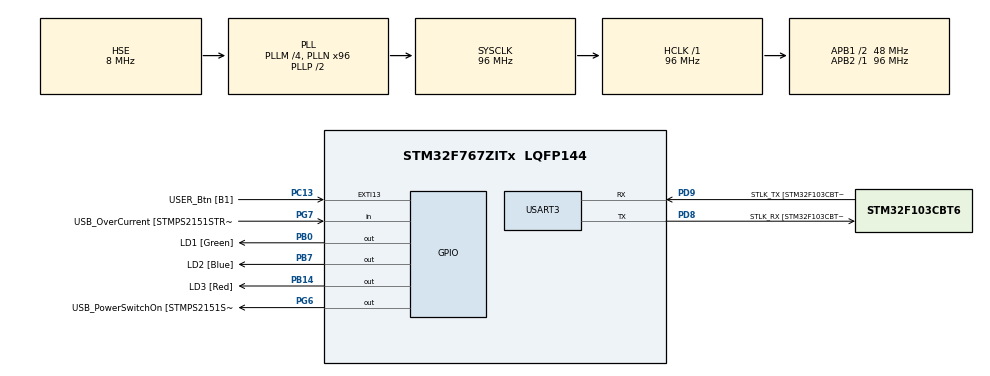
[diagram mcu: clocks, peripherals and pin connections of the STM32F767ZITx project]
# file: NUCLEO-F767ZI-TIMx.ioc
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Mcu.Family=STM32F7
Mcu.Name=STM32F767ZITx
Mcu.Package=LQFP144
NVIC.PriorityGroup=NVIC_PRIORITYGROUP_4
PA13.GPIO_Label=TMS
PA13.Mode=Serial_Wire
PA13.Signal=SYS_JTMS-SWDIO
PA14.GPIO_Label=TCK
PA14.Mode=Serial_Wire
PA14.Signal=SYS_JTCK-SWCLK
PB0.GPIO_Label=LD1 [Green]
PB0.Signal=GPIO_Output
PB14.GPIO_Label=LD3 [Red]
PB14.Signal=GPIO_Output
PB3.GPIO_Label=SWO
PB3.Signal=SYS_JTDO-SWO
PB7.GPIO_Label=LD2 [Blue]
PB7.Signal=GPIO_Output
PC13.GPIO_Label=USER_Btn [B1]
PC13.Signal=GPXTI13
PC14/OSC32_IN.Mode=LSE-External-Oscillator
PC14/OSC32_IN.Signal=RCC_OSC32_IN
PC15/OSC32_OUT.Mode=LSE-External-Oscillator
PC15/OSC32_OUT.Signal=RCC_OSC32_OUT
PD8.GPIO_Label=STLK_RX [STM32F103CBT6_PA3]
PD8.Mode=Asynchronous
PD8.Signal=USART3_TX
PD9.GPIO_Label=STLK_TX [STM32F103CBT6_PA2]
PD9.Mode=Asynchronous
PD9.Signal=USART3_RX
PG6.GPIO_Label=USB_PowerSwitchOn [STMPS2151STR_EN]
PG6.Signal=GPIO_Output
PG7.GPIO_Label=USB_OverCurrent [STMPS2151STR_FAULT]
PG7.Signal=GPIO_Input
PH0/OSC_IN.GPIO_Label=MCO [STM32F103CBT6_PA8]
PH0/OSC_IN.Mode=HSE-External-Clock-Source
PH0/OSC_IN.Signal=RCC_OSC_IN
PH1/OSC_OUT.Mode=HSE-External-Clock-Source
PH1/OSC_OUT.Signal=RCC_OSC_OUT
ProjectManager.HeapSize=0x200
ProjectManager.StackSize=0x400
ProjectManager.TargetToolchain=STM32CubeIDE
RCC.48MHZClocksFreq_Value=24000000
RCC.AHBFreq_Value=96000000
RCC.APB1CLKDivider=RCC_HCLK_DIV2
RCC.APB1Freq_Value=48000000
RCC.APB1TimFreq_Value=96000000
RCC.APB2Freq_Value=96000000
RCC.APB2TimFreq_Value=96000000
RCC.CortexFreq_Value=96000000
RCC.HCLKFreq_Value=96000000
RCC.HSE_VALUE=8000000
RCC.HSI_VALUE=16000000
RCC.PLLM=4
RCC.PLLMUL=RCC_PLL_MUL9
RCC.PLLN=96
RCC.PLLQ=4
RCC.PLLSourceVirtual=RCC_PLLSOURCE_HSE
RCC.PRESCALERUSB=RCC_USBCLKSOURCE_PLL_DIV1_5
RCC.SYSCLKFreq_VALUE=96000000
RCC.SYSCLKSource=RCC_SYSCLKSOURCE_PLLCLK
RCC.SYSCLKSourceVirtual=RCC_SYSCLKSOURCE_PLLCLK
RCC.USBFreq_Value=48000000
RCC.VCOOutputFreq_Value=192000000
USART3.VirtualMode-Asynchronous=VM_ASYNC
board=NUCLEO-F767ZI

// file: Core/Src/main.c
/* USER CODE BEGIN Header */
/**
  ******************************************************************************
  * @file           : main.c
  * @brief          : Main program body
  ******************************************************************************
  * @attention
  *
  * Copyright (c) 2022 STMicroelectronics.
  * All rights reserved.
  *
  * This software is licensed under terms that can be found in the LICENSE file
  * in the root directory of this software component.
  * If no LICENSE file comes with this software, it is provided AS-IS.
  *
  ******************************************************************************
  */
/* USER CODE END Header */
#include "main.h"
#include "usart.h"
#include "gpio.h"

void SystemClock_Config(void);

/* USER CODE BEGIN 0 */
static void DMA_Init()
{
  __HAL_RCC_DMA1_CLK_ENABLE();
  __HAL_RCC_DMA2_CLK_ENABLE();
}
/* USER CODE END 0 */

int main(void)
{

  /* MCU Configuration--------------------------------------------------------*/

  /* Reset of all peripherals, Initializes the Flash interface and the Systick. */
  HAL_Init();

  /* Configure the system clock */
  SystemClock_Config();

  /* Initialize all configured peripherals */
  MX_GPIO_Init();
  MX_USART3_UART_Init();
  /* USER CODE BEGIN 2 */
  DMA_Init();
  /* USER CODE END 2 */

  /* Infinite loop */
  /* USER CODE BEGIN WHILE */
  extern void TestFunction();
  TestFunction();

  while (1)
  {
    /* USER CODE END WHILE */

  }
}

void SystemClock_Config(void)
{
  RCC_OscInitTypeDef RCC_OscInitStruct = {0};
  RCC_ClkInitTypeDef RCC_ClkInitStruct = {0};

  /** Configure LSE Drive Capability
  */
  HAL_PWR_EnableBkUpAccess();

  /** Configure the main internal regulator output voltage
  */
  __HAL_RCC_PWR_CLK_ENABLE();
  __HAL_PWR_VOLTAGESCALING_CONFIG(PWR_REGULATOR_VOLTAGE_SCALE3);

  /** Initializes the RCC Oscillators according to the specified parameters
  * in the RCC_OscInitTypeDef structure.
  */
  RCC_OscInitStruct.OscillatorType = RCC_OSCILLATORTYPE_HSE;
  RCC_OscInitStruct.HSEState = RCC_HSE_BYPASS;
  RCC_OscInitStruct.PLL.PLLState = RCC_PLL_ON;
  RCC_OscInitStruct.PLL.PLLSource = RCC_PLLSOURCE_HSE;
  RCC_OscInitStruct.PLL.PLLM = 4;
  RCC_OscInitStruct.PLL.PLLN = 96;
  RCC_OscInitStruct.PLL.PLLP = RCC_PLLP_DIV2;
  RCC_OscInitStruct.PLL.PLLQ = 4;
  RCC_OscInitStruct.PLL.PLLR = 2;
  if (HAL_RCC_OscConfig(&RCC_OscInitStruct) != HAL_OK)
  {
    Error_Handler();
  }

  /** Activate the Over-Drive mode
  */
  if (HAL_PWREx_EnableOverDrive() != HAL_OK)
  {
    Error_Handler();
  }

  /** Initializes the CPU, AHB and APB buses clocks
  */
  RCC_ClkInitStruct.ClockType = RCC_CLOCKTYPE_HCLK|RCC_CLOCKTYPE_SYSCLK
                              |RCC_CLOCKTYPE_PCLK1|RCC_CLOCKTYPE_PCLK2;
  RCC_ClkInitStruct.SYSCLKSource = RCC_SYSCLKSOURCE_PLLCLK;
  RCC_ClkInitStruct.AHBCLKDivider = RCC_SYSCLK_DIV1;
  RCC_ClkInitStruct.APB1CLKDivider = RCC_HCLK_DIV2;
  RCC_ClkInitStruct.APB2CLKDivider = RCC_HCLK_DIV1;

  if (HAL_RCC_ClockConfig(&RCC_ClkInitStruct, FLASH_LATENCY_3) != HAL_OK)
  {
    Error_Handler();
  }
}

void Error_Handler(void)
{
  /* USER CODE BEGIN Error_Handler_Debug */
  /* User can add his own implementation to report the HAL error return state */

  __disable_irq();
  HAL_GPIO_WritePin(LD3_GPIO_Port, LD3_Pin, GPIO_PIN_SET);

  while (1);
  /* USER CODE END Error_Handler_Debug */
}
